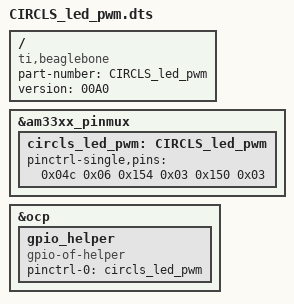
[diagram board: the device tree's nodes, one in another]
/*
* Copyright (C) 2012 Texas Instruments Incorporated - http://www.ti.com/
*
* This program is free software; you can redistribute it and/or modify
* it under the terms of the GNU General Purpose License Version 2 as
* published by the Free Software Foundation
*
* Original from: github.com/jadonk/validation-scripts/blob/master/test-capemgr/
*
* Modified by Derek Molloy for the example on www.derekmolloy.ie
* that maps GPIO pins for the example
*
* Modified again by Fritz Reese for a custom RGB LED circuit.
*
* Note until I can figure out the right way to "expose" the duty etc. pins as
* they are in the conveniently missing PWM modules, here is a reference for the
* 'export' pins to use for /sys/class/pwm.
*
* export	name		pins
* 0		ehrpwm0a	p9.22, p9.31
* 1		ehrpwm0b	p9.21, p9.29
* 2		ehrpwm0 	p9.42
* 3		ehrpwm1a	p9.14, p8.36
* 4		ehrpwm1b	p9.16, p8.34
* 5		ehrpwm2a	p8.19, p8.45
* 6		ehrpwm2b	p8.13, p8.46
* 7		ehrpwm2 	p9.28
*
*/

/dts-v1/;
/plugin/;

/{
  compatible = "ti,beaglebone", "ti,beaglebone-black";
  part-number = "CIRCLS_led_pwm";
  version = "00A0";

  fragment@0 {
    target = <&am33xx_pinmux>;

    __overlay__ {
      circls_led_pwm: CIRCLS_led_pwm {
        pinctrl-single,pins = <
          0x04c 0x06  // P9_16 PINS$19 EHRPWM1B
          0x154 0x03  // P9_21 PINS$85 EHRPWM0B
          0x150 0x03  // P9_22 PINS$84 EHRPWM0A
        >;
      };
    };
  };

  fragment@1 {
    target = <&ocp>;
    __overlay__ {
      gpio_helper {
        compatible = "gpio-of-helper";
        status = "okay";
        pinctrl-names = "default";
        pinctrl-0 = <&circls_led_pwm>;
      };
    };
  };
};
